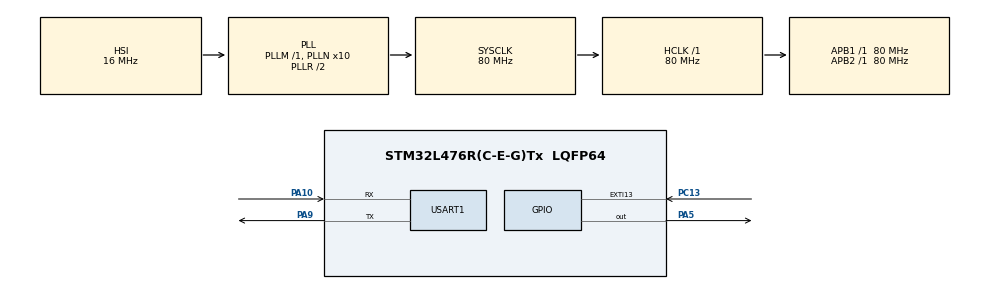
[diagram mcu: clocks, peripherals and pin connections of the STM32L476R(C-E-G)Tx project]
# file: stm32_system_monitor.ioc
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Mcu.Family=STM32L4
Mcu.Name=STM32L476R(C-E-G)Tx
Mcu.Package=LQFP64
NUCLEO-L476RG.BUTTON=1
NUCLEO-L476RG.LD2=true
NVIC.EXTI15_10_IRQn=true\:0\:0\:false\:false\:true\:false\:true\:true
NVIC.PriorityGroup=NVIC_PRIORITYGROUP_4
NVIC.USART1_IRQn=true\:0\:0\:false\:false\:true\:true\:true\:true
PA10.Mode=Asynchronous
PA10.Signal=USART1_RX
PA13\ (JTMS-SWDIO).GPIO_Label=TMS
PA13\ (JTMS-SWDIO).Signal=SYS_JTMS-SWDIO
PA14\ (JTCK-SWCLK).GPIO_Label=TCK
PA14\ (JTCK-SWCLK).Signal=SYS_JTCK-SWCLK
PA5.Signal=GPIO_Output
PA9.Mode=Asynchronous
PA9.Signal=USART1_TX
PB3\ (JTDO-TRACESWO).GPIO_Label=SWO
PB3\ (JTDO-TRACESWO).Signal=SYS_JTDO-SWO
PC13.Signal=GPXTI13
PC14-OSC32_IN\ (PC14).Signal=RCC_OSC32_IN
PC15-OSC32_OUT\ (PC15).Signal=RCC_OSC32_OUT
PH0-OSC_IN\ (PH0).Signal=RCC_OSC_IN
PH1-OSC_OUT\ (PH1).Signal=RCC_OSC_OUT
ProjectManager.HeapSize=0x200
ProjectManager.StackSize=0x400
ProjectManager.TargetToolchain=STM32CubeIDE
RCC.ADCFreq_Value=64000000
RCC.AHBFreq_Value=80000000
RCC.APB1Freq_Value=80000000
RCC.APB1TimFreq_Value=80000000
RCC.APB2Freq_Value=80000000
RCC.APB2TimFreq_Value=80000000
RCC.CortexFreq_Value=80000000
RCC.HCLKFreq_Value=80000000
RCC.HSE_VALUE=8000000
RCC.HSI_VALUE=16000000
RCC.LSE_VALUE=32768
RCC.MSI_VALUE=4000000
RCC.PLLN=10
RCC.PLLSourceVirtual=RCC_PLLSOURCE_HSI
RCC.PREFETCH_ENABLE=1
RCC.SYSCLKFreq_VALUE=80000000
RCC.SYSCLKSource=RCC_SYSCLKSOURCE_PLLCLK
RCC.USBFreq_Value=64000000
RCC.VCOOutputFreq_Value=160000000
USART1.VirtualMode-Asynchronous=VM_ASYNC
VP_NUCLEO-L476RG_VS_BSP_COMMON.Mode=COMMON
board=NUCLEO-L476RG

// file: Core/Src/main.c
/* USER CODE BEGIN Header */
/**
  ******************************************************************************
  * @file           : main.c
  * @brief          : Main program body
  ******************************************************************************
  * @attention
  *
  * Copyright (c) 2026 STMicroelectronics.
  * All rights reserved.
  *
  * This software is licensed under terms that can be found in the LICENSE file
  * in the root directory of this software component.
  * If no LICENSE file comes with this software, it is provided AS-IS.
  *
  ******************************************************************************
  */
/* USER CODE END Header */
#include "main.h"

/* USER CODE BEGIN Includes */
#include "com.h"
#include "protocol.h"
#include "string.h"
#include "crc.h"
/* USER CODE END Includes */

UART_HandleTypeDef huart1;

void SystemClock_Config(void);
static void MX_GPIO_Init(void);
static void MX_USART1_UART_Init(void);

int main(void)
{

  /* MCU Configuration--------------------------------------------------------*/

  /* Reset of all peripherals, Initializes the Flash interface and the Systick. */
  HAL_Init();

  /* Configure the system clock */
  SystemClock_Config();

  /* Initialize all configured peripherals */
  MX_GPIO_Init();
  MX_USART1_UART_Init();
  /* USER CODE BEGIN 2 */
  com_init();
  /* USER CODE END 2 */

  /* Initialize leds */
  BSP_LED_Init(LED_GREEN);

  /* Initialize USER push-button, will be used to trigger an interrupt each time it's pressed.*/
  BSP_PB_Init(BUTTON_USER, BUTTON_MODE_EXTI);

  /* Infinite loop */
  /* USER CODE BEGIN WHILE */

  while (1)
  {
	com_process();
    /* USER CODE END WHILE */

  }
}

void SystemClock_Config(void)
{
  RCC_OscInitTypeDef RCC_OscInitStruct = {0};
  RCC_ClkInitTypeDef RCC_ClkInitStruct = {0};

  /** Configure the main internal regulator output voltage
  */
  if (HAL_PWREx_ControlVoltageScaling(PWR_REGULATOR_VOLTAGE_SCALE1) != HAL_OK)
  {
    Error_Handler();
  }

  /** Initializes the RCC Oscillators according to the specified parameters
  * in the RCC_OscInitTypeDef structure.
  */
  RCC_OscInitStruct.OscillatorType = RCC_OSCILLATORTYPE_HSI;
  RCC_OscInitStruct.HSIState = RCC_HSI_ON;
  RCC_OscInitStruct.HSICalibrationValue = RCC_HSICALIBRATION_DEFAULT;
  RCC_OscInitStruct.PLL.PLLState = RCC_PLL_ON;
  RCC_OscInitStruct.PLL.PLLSource = RCC_PLLSOURCE_HSI;
  RCC_OscInitStruct.PLL.PLLM = 1;
  RCC_OscInitStruct.PLL.PLLN = 10;
  RCC_OscInitStruct.PLL.PLLP = RCC_PLLP_DIV7;
  RCC_OscInitStruct.PLL.PLLQ = RCC_PLLQ_DIV2;
  RCC_OscInitStruct.PLL.PLLR = RCC_PLLR_DIV2;
  if (HAL_RCC_OscConfig(&RCC_OscInitStruct) != HAL_OK)
  {
    Error_Handler();
  }

  /** Initializes the CPU, AHB and APB buses clocks
  */
  RCC_ClkInitStruct.ClockType = RCC_CLOCKTYPE_HCLK|RCC_CLOCKTYPE_SYSCLK
                              |RCC_CLOCKTYPE_PCLK1|RCC_CLOCKTYPE_PCLK2;
  RCC_ClkInitStruct.SYSCLKSource = RCC_SYSCLKSOURCE_PLLCLK;
  RCC_ClkInitStruct.AHBCLKDivider = RCC_SYSCLK_DIV1;
  RCC_ClkInitStruct.APB1CLKDivider = RCC_HCLK_DIV1;
  RCC_ClkInitStruct.APB2CLKDivider = RCC_HCLK_DIV1;

  if (HAL_RCC_ClockConfig(&RCC_ClkInitStruct, FLASH_LATENCY_4) != HAL_OK)
  {
    Error_Handler();
  }
}

static void MX_USART1_UART_Init(void)
{

  huart1.Instance = USART1;
  huart1.Init.BaudRate = 115200;
  huart1.Init.WordLength = UART_WORDLENGTH_8B;
  huart1.Init.StopBits = UART_STOPBITS_1;
  huart1.Init.Parity = UART_PARITY_NONE;
  huart1.Init.Mode = UART_MODE_TX_RX;
  huart1.Init.HwFlowCtl = UART_HWCONTROL_NONE;
  huart1.Init.OverSampling = UART_OVERSAMPLING_16;
  huart1.Init.OneBitSampling = UART_ONE_BIT_SAMPLE_DISABLE;
  huart1.AdvancedInit.AdvFeatureInit = UART_ADVFEATURE_NO_INIT;
  if (HAL_UART_Init(&huart1) != HAL_OK)
  {
    Error_Handler();
  }

}

static void MX_GPIO_Init(void)
{

  /* GPIO Ports Clock Enable */
  __HAL_RCC_GPIOC_CLK_ENABLE();
  __HAL_RCC_GPIOH_CLK_ENABLE();
  __HAL_RCC_GPIOA_CLK_ENABLE();
  __HAL_RCC_GPIOB_CLK_ENABLE();

}

void Error_Handler(void)
{
  __disable_irq();
  while (1)
  {
  }
}
